# CH32V103xx register map
Vendor: WCH Ltd.; File version: 1.1
Registers are 32-bit, read-write, reset 0x0 unless marked. A register's access mark holds for its fields unless they carry their own. Offsets are from the block's base; [hi:lo] are bit positions; {n}, {i} and the like mark numbered series.

## DBG — Debug support
Base 0xE000D000
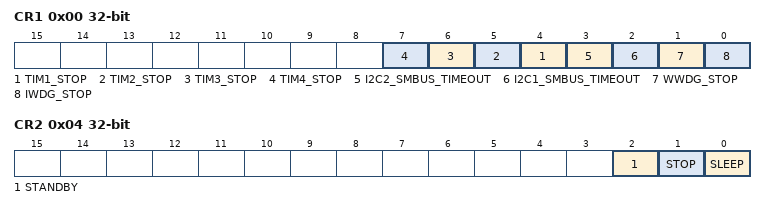
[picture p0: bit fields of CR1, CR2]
0x00 CR1 — DBGMCU_CR1
  [n+3] TIM{n}_STOP (n=1..4), [3] I2C2_SMBUS_TIMEOUT, [2] I2C1_SMBUS_TIMEOUT, [1] WWDG_STOP, [0] IWDG_STOP
0x04 CR2 — DBGMCU_CR2
  [2] STANDBY — DBG_STANDBY
  [1] STOP — DBG_STOP
  [0] SLEEP — DBG_SLEEP

## CRC — CRC calculation unit
Base 0x40023000
0x00 DATAR reset 0xFFFFFFFF — Data register
  [31:0] DATA
0x04 IDATAR 8-bit — Independent Data register
  [7:0] IDATA
0x08 CTLR wo — Control register
  [0] RST — Reset bit

## FLASH
Base 0x40022000
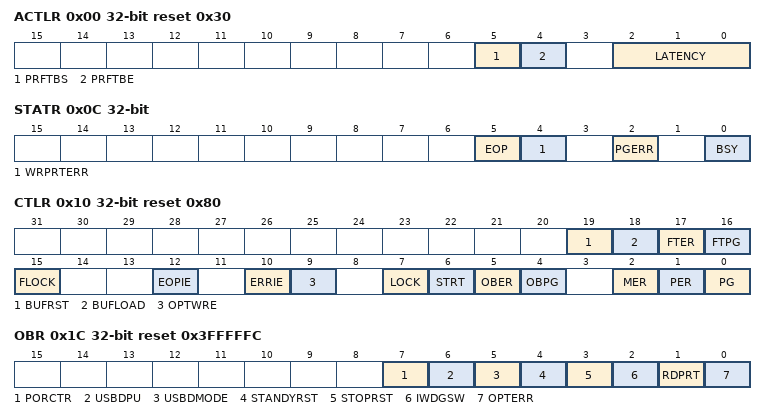
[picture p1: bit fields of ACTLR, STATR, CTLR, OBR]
0x00 ACTLR access per field reset 0x30 — Flash access control register
  [5] PRFTBS ro — Prefetch buffer status
  [4] PRFTBE rw — Prefetch buffer enable
  [2:0] LATENCY rw
0x04 KEYR wo — Flash key register
  [31:0] KEYR — FPEC key
0x08 OBKEYR wo — Flash option key register
  [31:0] OBKEYR — Option byte key
0x0C STATR access per field — Status register
  [5] EOP rw — End of operation
  [4] WRPRTERR rw — Write protection error
  [2] PGERR rw — Programming error
  [0] BSY ro — Busy
0x10 CTLR reset 0x80 — Control register
  [19] BUFRST — execute inner buffer reset
  [18] BUFLOAD — execute data load inner buffer
  [17] FTER — execute fast 128byte erase
  [16] FTPG — execute fast programming
  [15] FLOCK — FAST programming lock
  [12] EOPIE — End of operation interrupt enable
  [10] ERRIE — Error interrupt enable
  [9] OPTWRE — Option bytes write enable
  [7] LOCK
  [6] STRT — Start
  [5] OBER — Option byte erase
  [4] OBPG — Option byte programming
  [2] MER — Mass Erase
  [1] PER — Page Erase
  [0] PG — Programming
0x14 ADDR wo — Flash address register
  [31:0] FAR — Flash Address
0x1C OBR ro reset 0x3FFFFFC — Option byte register
  [7] PORCTR — Power on reset time
  [6] USBDPU — USBD compatible inner pull up resistance configure
  [5] USBDMODE — USBD compatible speed mode configure
  [4] STANDYRST — nRST_STDBY
  [3] STOPRST — nRST_STOP
  [2] IWDGSW
  [1] RDPRT — Read protection
  [0] OPTERR — Option byte error
0x20 WPR ro — Write protection register
  [31:0] WRP — Write protect
0x24 MODEKEYR wo — Extension key register
  [31:0] MODEKEYR — high speed write /erase mode ENABLE

## PFIC — Programmable Fast Interrupt Controller
Base 0xE000E000
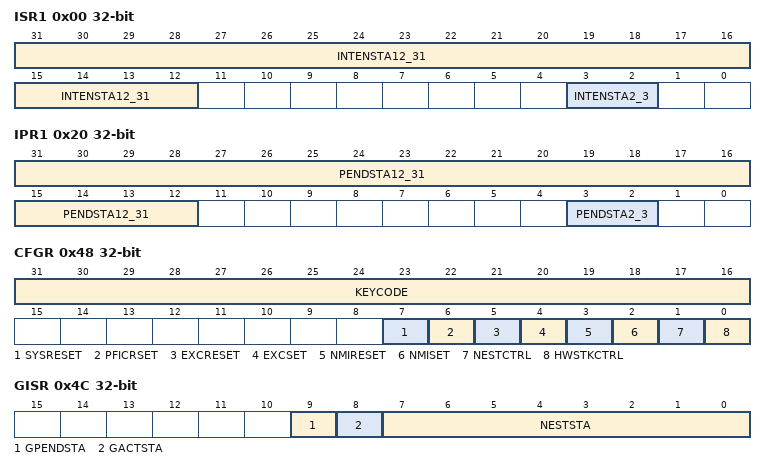
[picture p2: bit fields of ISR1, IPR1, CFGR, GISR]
0x00 ISR1 ro — Interrupt Status Register
  [31:12] INTENSTA12_31 — Interrupt ID Status
  [3:2] INTENSTA2_3 — Interrupt ID Status
0x04 ISR2 ro — Interrupt Status Register
  [27:0] INTENSTA — Interrupt ID Status
0x20 IPR1 ro — Interrupt Pending Register
  [31:12] PENDSTA12_31 — PENDSTA
  [3:2] PENDSTA2_3 — PENDSTA
0x24 IPR2 ro — Interrupt Pending Register
  [27:0] PENDSTA
0x40 ITHRESDR — Interrupt Priority Register
  [7:0] THRESHOLD
0x44 FIBADDRR — Interrupt Fast Address Register
  [31:28] BASEADDR
0x48 CFGR access per field — Interrupt Config Register
  [31:16] KEYCODE wo, [7] SYSRESET wo, [6] PFICRSET wo, [5] EXCRESET wo, [4] EXCSET wo, [3] NMIRESET wo, [2] NMISET wo, [1] NESTCTRL rw, [0] HWSTKCTRL rw
0x4C GISR ro — Interrupt Global Register
  [9] GPENDSTA, [8] GACTSTA, [7:0] NESTSTA
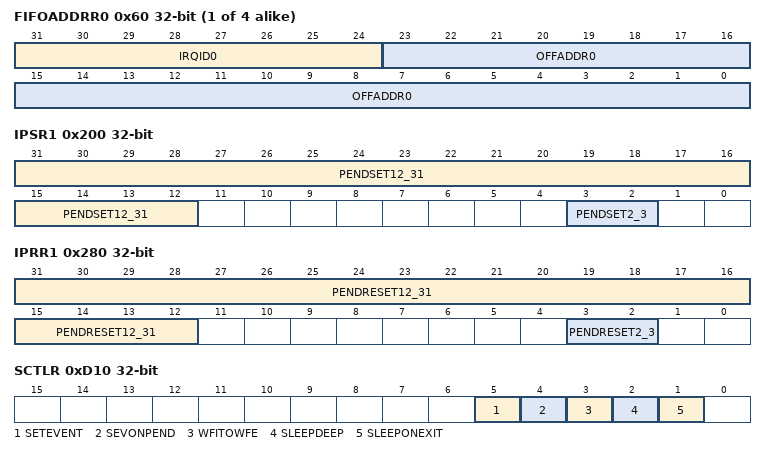
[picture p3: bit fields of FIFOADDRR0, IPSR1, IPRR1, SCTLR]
{0x60+4i} FIFOADDRR{i} (i=0..3) — Interrupt {i} address Register
  [31:24] IRQID{i}, [23:0] OFFADDR{i}
0x100 IENR1 — Interrupt Setting Register
  [31:12] INTEN
0x104 IENR2 — Interrupt Setting Register
  [27:0] INTEN
0x180 IRER1 — Interrupt Clear Register
  [31:12] INTRSET
0x184 IRER2 — Interrupt Clear Register
  [27:0] INTRSET
0x200 IPSR1 — Interrupt Pending Register
  [31:12] PENDSET12_31 — PENDSET
  [3:2] PENDSET2_3 — PENDSET
0x204 IPSR2 — Interrupt Pending Register
  [27:0] PENDSET
0x280 IPRR1 — Interrupt Pending Clear Register
  [31:12] PENDRESET12_31 — PENDRESET
  [3:2] PENDRESET2_3 — PENDRESET
0x284 IPRR2 — Interrupt Pending Clear Register
  [27:0] PENDRESET
0x300 IACTR1 — Interrupt ACTIVE Register
  [31:12] IACTS
0x304 IACTR2 — Interrupt ACTIVE Register
  [27:0] IACTS
0xD10 SCTLR — System Control Register
  [5] SETEVENT, [4] SEVONPEND, [3] WFITOWFE, [2] SLEEPDEEP, [1] SLEEPONEXIT
0x1000 STK_CTLR — System counting Control Register
  [27:0] STE

## USBD — Universal serial bus full-speed device interface
Base 0x40005C00
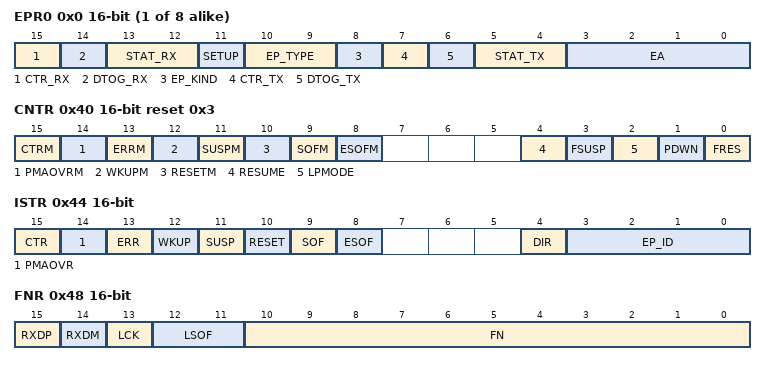
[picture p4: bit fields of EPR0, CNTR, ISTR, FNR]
{0x0+4i} EPR{i} 16-bit (i=0..7) — endpoint {i} register
  [15] CTR_RX — Correct transfer for reception
  [14] DTOG_RX — Data Toggle, for reception transfers
  [13:12] STAT_RX — Status bits, for reception transfers
  [11] SETUP — Setup transaction completed
  [10:9] EP_TYPE — Endpoint type
  [8] EP_KIND — Endpoint kind
  [7] CTR_TX — Correct Transfer for transmission
  [6] DTOG_TX — Data Toggle, for transmission transfers
  [5:4] STAT_TX — Status bits, for transmission transfers
  [3:0] EA — Endpoint address
0x40 CNTR 16-bit reset 0x3 — control register
  [15] CTRM — Correct transfer interrupt mask
  [14] PMAOVRM — Packet memory area over / underrun interrupt mask
  [13] ERRM — Error interrupt mask
  [12] WKUPM — Wakeup interrupt mask
  [11] SUSPM — Suspend mode interrupt mask
  [10] RESETM — USB reset interrupt mask
  [9] SOFM — Start of frame interrupt mask
  [8] ESOFM — Expected start of frame interrupt mask
  [4] RESUME — Resume request
  [3] FSUSP — Force suspend
  [2] LPMODE — Low-power mode
  [1] PDWN — Power down
  [0] FRES — Force USB Reset
0x44 ISTR 16-bit — interrupt status register
  [15] CTR — Correct transfer
  [14] PMAOVR — Packet memory area over / underrun
  [13] ERR — Error
  [12] WKUP — Wakeup
  [11] SUSP — Suspend mode request
  [10] RESET — reset request
  [9] SOF — start of frame
  [8] ESOF — Expected start frame
  [4] DIR — Direction of transaction
  [3:0] EP_ID — Endpoint Identifier
0x48 FNR 16-bit ro — frame number register
  [15] RXDP — Receive data + line status
  [14] RXDM — Receive data - line status
  [13] LCK — Locked
  [12:11] LSOF — Lost SOF
  [10:0] FN — Frame number
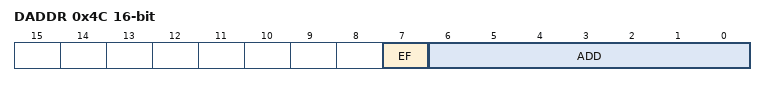
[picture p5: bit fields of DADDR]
0x4C DADDR 16-bit — device address
  [7] EF — Enable function
  [6:0] ADD — Device address
0x50 BTABLE 16-bit — Buffer table address
  [15:3] BTABLE — Buffer table

## ESIG — Device electronic signature
Base 0x1FFFF7E0
0x00 FLACAP 16-bit ro — Flash capacity register
  [15:0] F_SIZE_15_0 — Flash size
{0x4+4i} UNIID{i} ro (i=1..3) — Unique identity {i}
  [31:0] U_ID — Unique identity[{32i-1}:{32i-32}]
